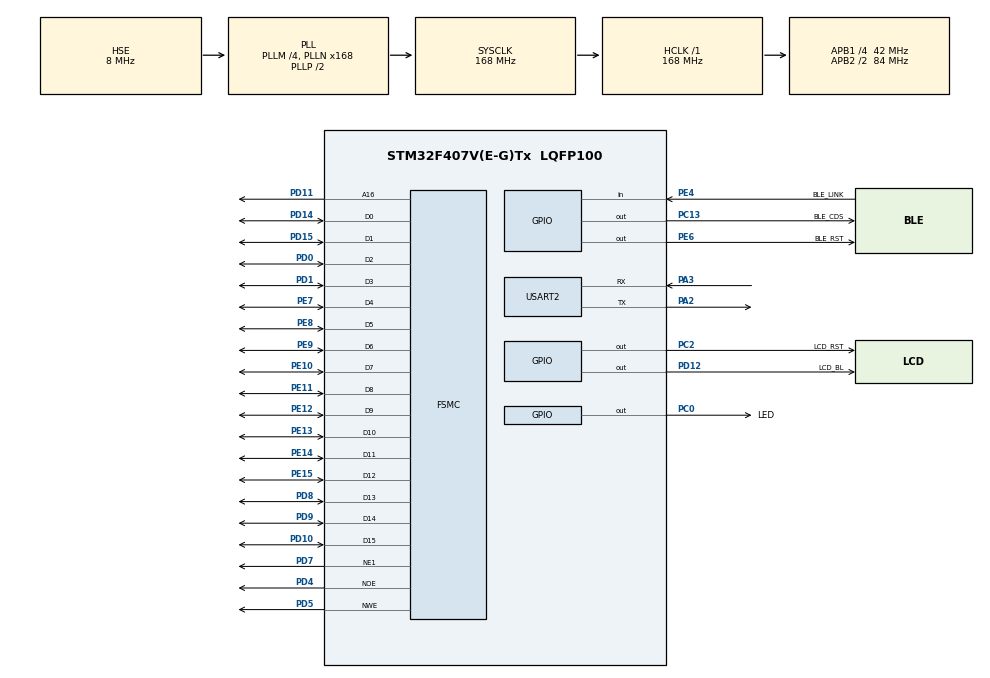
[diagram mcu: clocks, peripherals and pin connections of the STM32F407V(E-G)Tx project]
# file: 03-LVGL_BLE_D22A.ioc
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FSMC.AccessMode1=FSMC_ACCESS_MODE_A
FSMC.AddressSetupTime1=15
FSMC.BusTurnAroundDuration1=0
FSMC.DataSetupTime1=60
FSMC.ExtendedAccessMode1=FSMC_ACCESS_MODE_A
FSMC.ExtendedAddressSetupTime1=0
FSMC.ExtendedBusTurnAroundDuration1=0
FSMC.ExtendedDataSetupTime1=1
FSMC.ExtendedMode1=FSMC_EXTENDED_MODE_ENABLE
FSMC.NSBank1=FSMC_NORSRAM_BANK1
FSMC.WriteOperation1=FSMC_WRITE_OPERATION_ENABLE
Mcu.Family=STM32F4
Mcu.Name=STM32F407V(E-G)Tx
Mcu.Package=LQFP100
NVIC.PriorityGroup=NVIC_PRIORITYGROUP_4
NVIC.TIM6_DAC_IRQn=true\:0\:0\:false\:false\:true\:true\:true\:true
PA13.Mode=Serial_Wire
PA13.Signal=SYS_JTMS-SWDIO
PA14.Mode=Serial_Wire
PA14.Signal=SYS_JTCK-SWCLK
PA2.Mode=Asynchronous
PA2.Signal=USART2_TX
PA3.Mode=Asynchronous
PA3.Signal=USART2_RX
PC0.GPIO_Label=LED
PC0.PinState=GPIO_PIN_SET
PC0.Signal=GPIO_Output
PC13-ANTI_TAMP.GPIO_Label=BLE_CDS
PC13-ANTI_TAMP.PinState=GPIO_PIN_SET
PC13-ANTI_TAMP.Signal=GPIO_Output
PC14-OSC32_IN.Mode=LSE-External-Oscillator
PC14-OSC32_IN.Signal=RCC_OSC32_IN
PC15-OSC32_OUT.Mode=LSE-External-Oscillator
PC15-OSC32_OUT.Signal=RCC_OSC32_OUT
PC2.GPIO_Label=LCD_RST
PC2.GPIO_Speed=GPIO_SPEED_FREQ_VERY_HIGH
PC2.PinState=GPIO_PIN_SET
PC2.Signal=GPIO_Output
PD0.Mode=16b-d1
PD0.Signal=FSMC_D2
PD1.Mode=16b-d1
PD1.Signal=FSMC_D3
PD10.Mode=16b-d1
PD10.Signal=FSMC_D15
PD11.Mode=A16_1
PD11.Signal=FSMC_A16
PD12.GPIO_Label=LCD_BL
PD12.GPIO_Speed=GPIO_SPEED_FREQ_VERY_HIGH
PD12.Signal=GPIO_Output
PD14.Mode=16b-d1
PD14.Signal=FSMC_D0
PD15.Mode=16b-d1
PD15.Signal=FSMC_D1
PD4.Mode=Lcd1
PD4.Signal=FSMC_NOE
PD5.Mode=Lcd1
PD5.Signal=FSMC_NWE
PD7.Mode=NorPsramChipSelect1_1
PD7.Signal=FSMC_NE1
PD8.Mode=16b-d1
PD8.Signal=FSMC_D13
PD9.Mode=16b-d1
PD9.Signal=FSMC_D14
PE10.Mode=16b-d1
PE10.Signal=FSMC_D7
PE11.Mode=16b-d1
PE11.Signal=FSMC_D8
PE12.Mode=16b-d1
PE12.Signal=FSMC_D9
PE13.Mode=16b-d1
PE13.Signal=FSMC_D10
PE14.Mode=16b-d1
PE14.Signal=FSMC_D11
PE15.Mode=16b-d1
PE15.Signal=FSMC_D12
PE4.GPIO_Label=BLE_LINK
PE4.Signal=GPIO_Input
PE6.GPIO_Label=BLE_RST
PE6.PinState=GPIO_PIN_SET
PE6.Signal=GPIO_Output
PE7.Mode=16b-d1
PE7.Signal=FSMC_D4
PE8.Mode=16b-d1
PE8.Signal=FSMC_D5
PE9.Mode=16b-d1
PE9.Signal=FSMC_D6
PH0-OSC_IN.Mode=HSE-External-Oscillator
PH0-OSC_IN.Signal=RCC_OSC_IN
PH1-OSC_OUT.Mode=HSE-External-Oscillator
PH1-OSC_OUT.Signal=RCC_OSC_OUT
ProjectManager.HeapSize=0x200
ProjectManager.StackSize=0x1000
ProjectManager.TargetToolchain=MDK-ARM V5.32
RCC.48MHZClocksFreq_Value=84000000
RCC.AHBFreq_Value=168000000
RCC.APB1CLKDivider=RCC_HCLK_DIV4
RCC.APB1Freq_Value=42000000
RCC.APB1TimFreq_Value=84000000
RCC.APB2CLKDivider=RCC_HCLK_DIV2
RCC.APB2Freq_Value=84000000
RCC.APB2TimFreq_Value=168000000
RCC.CortexFreq_Value=168000000
RCC.FLatency=FLASH_LATENCY_5
RCC.HCLKFreq_Value=168000000
RCC.HSE_VALUE=8000000
RCC.HSI_VALUE=16000000
RCC.PLLM=4
RCC.PLLN=168
RCC.PLLSourceVirtual=RCC_PLLSOURCE_HSE
RCC.SYSCLKFreq_VALUE=168000000
RCC.SYSCLKSource=RCC_SYSCLKSOURCE_PLLCLK
RCC.VCOOutputFreq_Value=336000000
TIM6.AutoReloadPreload=TIM_AUTORELOAD_PRELOAD_ENABLE
TIM6.CounterMode=TIM_COUNTERMODE_UP
TIM6.Period=1000-1
TIM6.Prescaler=84-1
TIM6.TIM_MasterOutputTrigger=TIM_TRGO_RESET
USART2.VirtualMode=VM_ASYNC
VP_TIM6_VS_ClockSourceINT.Mode=Enable_Timer
board=custom

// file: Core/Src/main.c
/* USER CODE BEGIN Header */
/**
  ******************************************************************************
  * @file           : main.c
  * @brief          : Main program body
  ******************************************************************************
  * @attention
  *
  * Copyright (c) 2024 STMicroelectronics.
  * All rights reserved.
  *
  * This software is licensed under terms that can be found in the LICENSE file
  * in the root directory of this software component.
  * If no LICENSE file comes with this software, it is provided AS-IS.
  *
  ******************************************************************************
  */
/* USER CODE END Header */
#include "main.h"
#include "tim.h"
#include "usart.h"
#include "gpio.h"
#include "fsmc.h"

/* USER CODE BEGIN Includes */

#include "lvgl.h"
#include "porting/lv_port_disp.h"

/* USER CODE END Includes */

void SystemClock_Config(void);

int main(void)
{

  /* MCU Configuration--------------------------------------------------------*/

  /* Reset of all peripherals, Initializes the Flash interface and the Systick. */
  HAL_Init();

  /* Configure the system clock */
  SystemClock_Config();

  /* Initialize all configured peripherals */
  MX_GPIO_Init();
  MX_FSMC_Init();
  MX_TIM6_Init();
  MX_USART2_UART_Init();

  /* Infinite loop */
  /* USER CODE BEGIN WHILE */

  HAL_TIM_Base_Start_IT(&htim6);

  lv_init();
  lv_port_disp_init();

  lv_obj_t *led = lv_led_create(lv_scr_act());

  while (1)
  {
	  lv_timer_handler();

    /* USER CODE END WHILE */

  }
}

void SystemClock_Config(void)
{
  RCC_OscInitTypeDef RCC_OscInitStruct = {0};
  RCC_ClkInitTypeDef RCC_ClkInitStruct = {0};

  /** Configure the main internal regulator output voltage
  */
  __HAL_RCC_PWR_CLK_ENABLE();
  __HAL_PWR_VOLTAGESCALING_CONFIG(PWR_REGULATOR_VOLTAGE_SCALE1);

  /** Initializes the RCC Oscillators according to the specified parameters
  * in the RCC_OscInitTypeDef structure.
  */
  RCC_OscInitStruct.OscillatorType = RCC_OSCILLATORTYPE_HSE;
  RCC_OscInitStruct.HSEState = RCC_HSE_ON;
  RCC_OscInitStruct.PLL.PLLState = RCC_PLL_ON;
  RCC_OscInitStruct.PLL.PLLSource = RCC_PLLSOURCE_HSE;
  RCC_OscInitStruct.PLL.PLLM = 4;
  RCC_OscInitStruct.PLL.PLLN = 168;
  RCC_OscInitStruct.PLL.PLLP = RCC_PLLP_DIV2;
  RCC_OscInitStruct.PLL.PLLQ = 4;
  if (HAL_RCC_OscConfig(&RCC_OscInitStruct) != HAL_OK)
  {
    Error_Handler();
  }

  /** Initializes the CPU, AHB and APB buses clocks
  */
  RCC_ClkInitStruct.ClockType = RCC_CLOCKTYPE_HCLK|RCC_CLOCKTYPE_SYSCLK
                              |RCC_CLOCKTYPE_PCLK1|RCC_CLOCKTYPE_PCLK2;
  RCC_ClkInitStruct.SYSCLKSource = RCC_SYSCLKSOURCE_PLLCLK;
  RCC_ClkInitStruct.AHBCLKDivider = RCC_SYSCLK_DIV1;
  RCC_ClkInitStruct.APB1CLKDivider = RCC_HCLK_DIV4;
  RCC_ClkInitStruct.APB2CLKDivider = RCC_HCLK_DIV2;

  if (HAL_RCC_ClockConfig(&RCC_ClkInitStruct, FLASH_LATENCY_5) != HAL_OK)
  {
    Error_Handler();
  }
}

void Error_Handler(void)
{
  __disable_irq();
  while (1)
  {
  }
}
